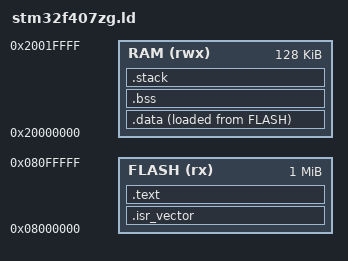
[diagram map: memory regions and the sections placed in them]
/*
 * STM32F407ZGT6 最小链接脚本。
 *   Flash 1MB   @ 0x08000000
 *   主 SRAM 128KB @ 0x20000000(CCM 64KB @ 0x10000000 暂未使用)
 *   栈顶 = SRAM 顶端 0x20020000(向下生长)
 */
ENTRY(Reset_Handler)

_estack = 0x20020000;

MEMORY
{
    FLASH (rx)  : ORIGIN = 0x08000000, LENGTH = 1024K
    RAM   (rwx) : ORIGIN = 0x20000000, LENGTH = 128K
}

SECTIONS
{
    .isr_vector :
    {
        . = ALIGN(4);
        KEEP(*(.isr_vector))
        . = ALIGN(4);
    } > FLASH

    .text :
    {
        . = ALIGN(4);
        *(.text*)
        *(.rodata*)
        . = ALIGN(4);
        _etext = .;
    } > FLASH

    _sidata = LOADADDR(.data);
    .data :
    {
        . = ALIGN(4);
        _sdata = .;
        *(.data*)
        . = ALIGN(4);
        _edata = .;
    } > RAM AT > FLASH

    .bss :
    {
        . = ALIGN(4);
        _sbss = .;
        *(.bss*)
        *(COMMON)
        . = ALIGN(4);
        _ebss = .;
    } > RAM

    .stack (NOLOAD) :
    {
        . = ALIGN(8);
        . = . + 0x400;
        . = ALIGN(8);
    } > RAM
}
